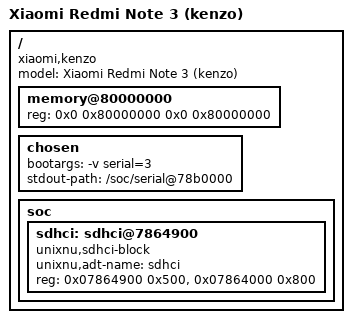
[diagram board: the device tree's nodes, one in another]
/dts-v1/;
/include/ "msm8956.dtsi"

/ {
    model = "Xiaomi Redmi Note 3 (kenzo)";
    compatible = "xiaomi,kenzo", "qcom,msm8956";

    memory@80000000 {
        device_type = "memory";
        // Captured unit: base 0x80000000, 2 GiB address range.
        reg = <0x0 0x80000000 0x0 0x80000000>;
    };

    chosen {
        bootargs = "-v serial=3";
        stdout-path = "/soc/serial@78b0000";
    };

    soc {
        // SDCC2 (external 32 GB microSD slot) hosts SHNGROOT (OS + SystemOS),
        // keeping internal eMMC (SDCC1) Android userdata 100% untouched.
        sdhci: sdhci@7864900 {
            unixnu,adt-name = "sdhci";
            compatible = "unixnu,sdhci-block", "qcom,sdhci-msm";
            reg = <0x07864900 0x500>,
                  <0x07864000 0x800>;
            status = "okay";
        };
    };
};
